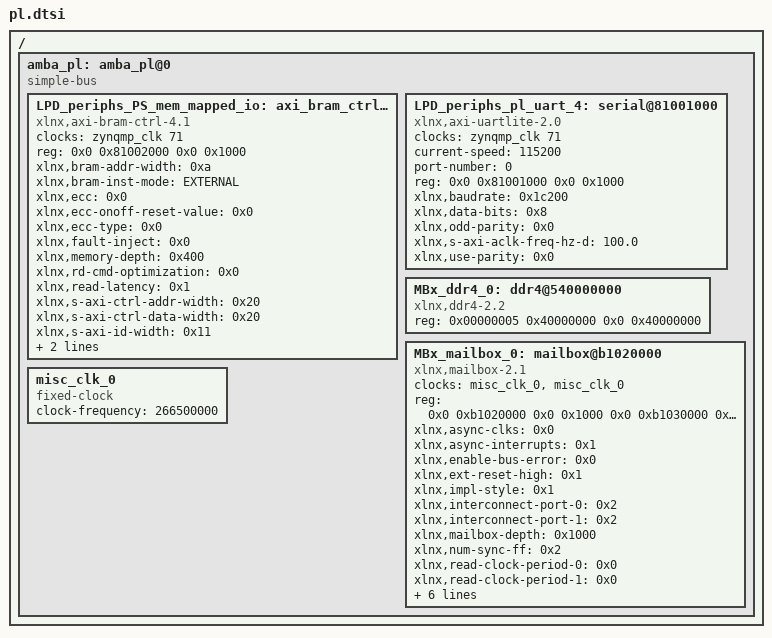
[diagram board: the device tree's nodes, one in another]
/*
 * CAUTION: This file is automatically generated by Xilinx.
 * Version:  
 * Today is: Sat Aug 20 15:46:44 2022
 */


/ {
	amba_pl: amba_pl@0 {
		#address-cells = <2>;
		#size-cells = <2>;
		compatible = "simple-bus";
		ranges ;
		LPD_periphs_PS_mem_mapped_io: axi_bram_ctrl@81002000 {
			clock-names = "s_axi_aclk";
			clocks = <&zynqmp_clk 71>;
			compatible = "xlnx,axi-bram-ctrl-4.1";
			reg = <0x0 0x81002000 0x0 0x1000>;
			xlnx,bram-addr-width = <0xa>;
			xlnx,bram-inst-mode = "EXTERNAL";
			xlnx,ecc = <0x0>;
			xlnx,ecc-onoff-reset-value = <0x0>;
			xlnx,ecc-type = <0x0>;
			xlnx,fault-inject = <0x0>;
			xlnx,memory-depth = <0x400>;
			xlnx,rd-cmd-optimization = <0x0>;
			xlnx,read-latency = <0x1>;
			xlnx,s-axi-ctrl-addr-width = <0x20>;
			xlnx,s-axi-ctrl-data-width = <0x20>;
			xlnx,s-axi-id-width = <0x11>;
			xlnx,s-axi-supports-narrow-burst = <0x1>;
			xlnx,single-port-bram = <0x1>;
		};
		LPD_periphs_pl_uart_4: serial@81001000 {
			clock-names = "s_axi_aclk";
			clocks = <&zynqmp_clk 71>;
			compatible = "xlnx,axi-uartlite-2.0", "xlnx,xps-uartlite-1.00.a";
			current-speed = <115200>;
			device_type = "serial";
			port-number = <0>;
			reg = <0x0 0x81001000 0x0 0x1000>;
			xlnx,baudrate = <0x1c200>;
			xlnx,data-bits = <0x8>;
			xlnx,odd-parity = <0x0>;
			xlnx,s-axi-aclk-freq-hz-d = "100.0";
			xlnx,use-parity = <0x0>;
		};
		MBx_ddr4_0: ddr4@540000000 {
			compatible = "xlnx,ddr4-2.2";
			reg = <0x00000005 0x40000000 0x0 0x40000000>;
		};
		MBx_mailbox_0: mailbox@b1020000 {
			clock-names = "S0_AXI_ACLK", "S1_AXI_ACLK";
			clocks = <&misc_clk_0>, <&misc_clk_0>;
			compatible = "xlnx,mailbox-2.1";
			reg = <0x0 0xb1020000 0x0 0x1000 0x0 0xb1030000 0x0 0x1000>;
			xlnx,async-clks = <0x0>;
			xlnx,async-interrupts = <0x1>;
			xlnx,enable-bus-error = <0x0>;
			xlnx,ext-reset-high = <0x1>;
			xlnx,impl-style = <0x1>;
			xlnx,interconnect-port-0 = <0x2>;
			xlnx,interconnect-port-1 = <0x2>;
			xlnx,mailbox-depth = <0x1000>;
			xlnx,num-sync-ff = <0x2>;
			xlnx,read-clock-period-0 = <0x0>;
			xlnx,read-clock-period-1 = <0x0>;
			xlnx,s0-axi-aclk-freq-mhz = "250.0";
			xlnx,s0-axi-addr-width = <0x20>;
			xlnx,s0-axi-data-width = <0x20>;
			xlnx,s1-axi-aclk-freq-mhz = "250.0";
			xlnx,s1-axi-addr-width = <0x20>;
			xlnx,s1-axi-data-width = <0x20>;
		};
		misc_clk_0: misc_clk_0 {
			#clock-cells = <0>;
			clock-frequency = <266500000>;
			compatible = "fixed-clock";
		};
	};
};
